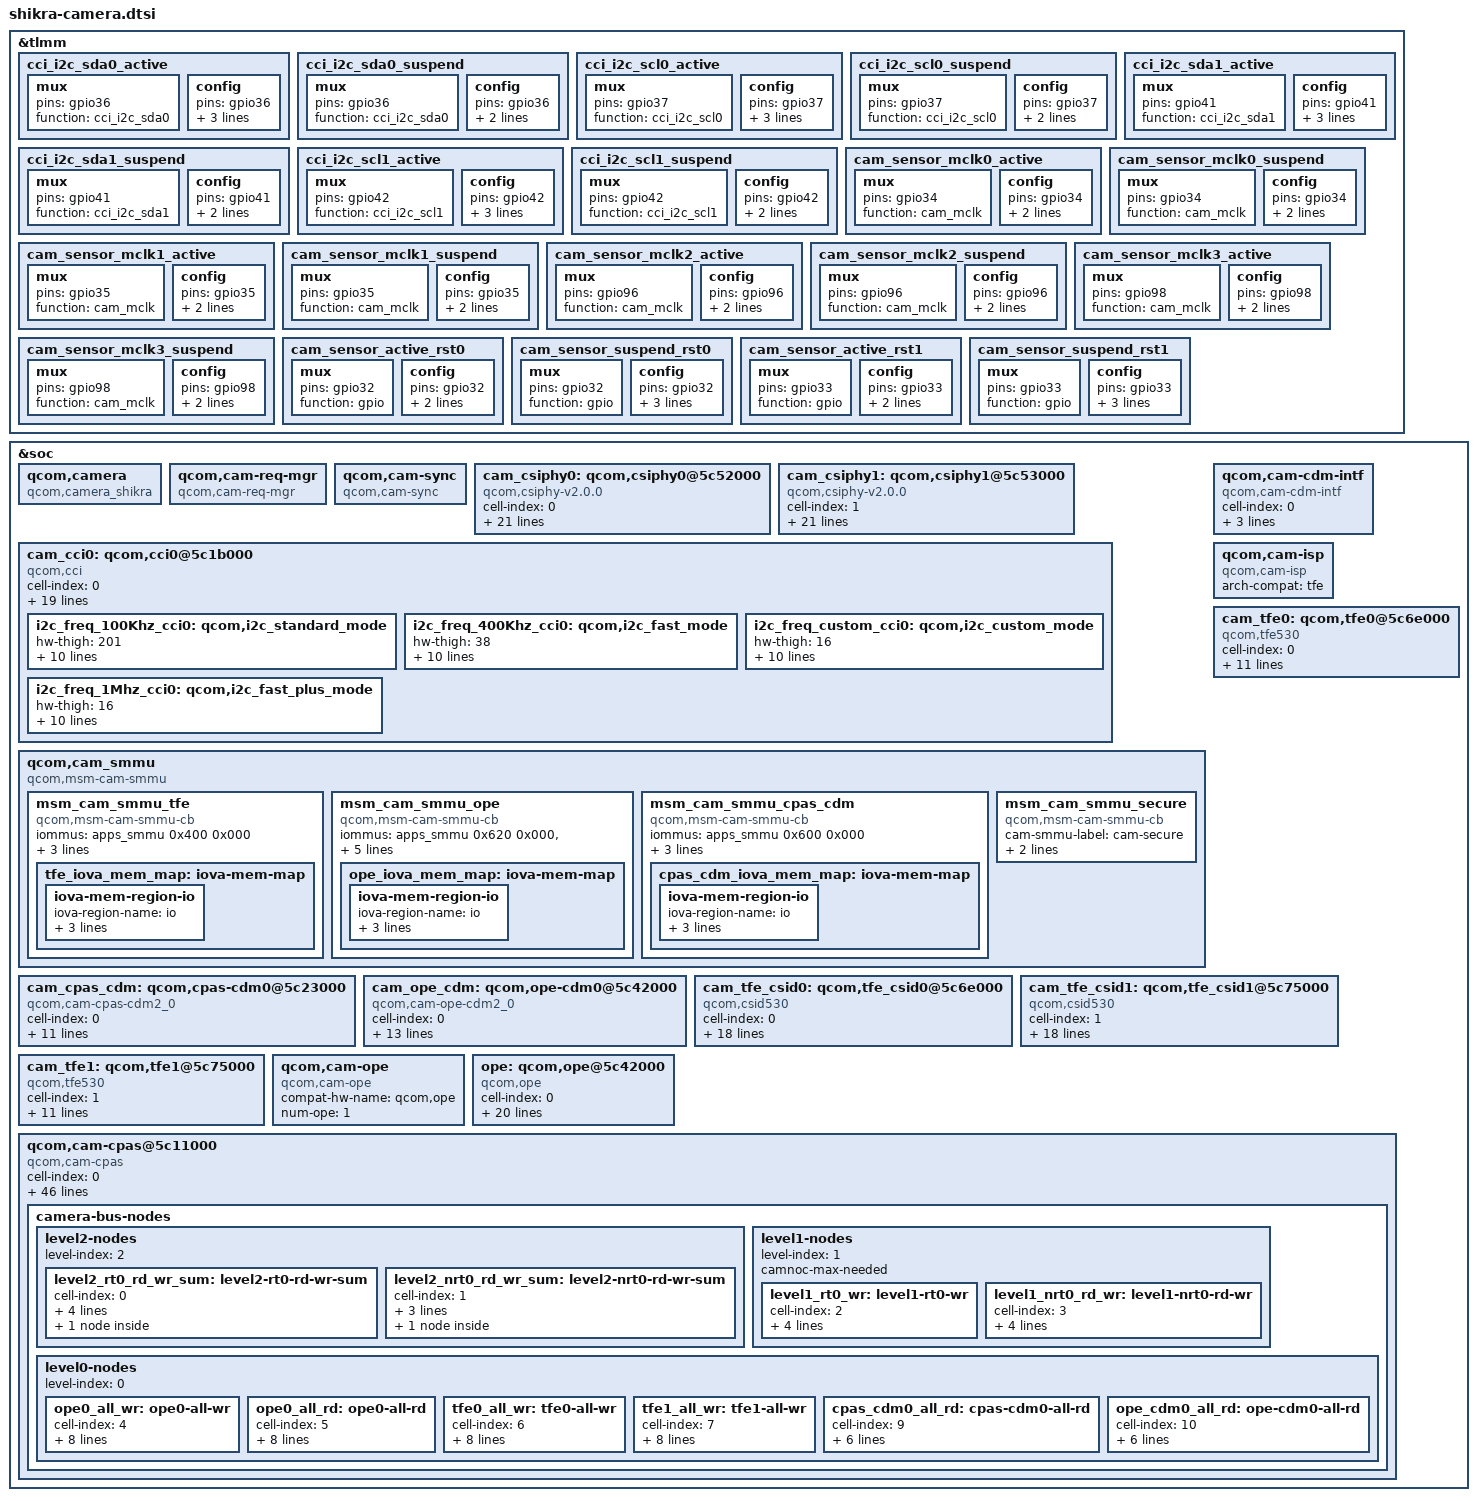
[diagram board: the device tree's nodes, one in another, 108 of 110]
// SPDX-License-Identifier: BSD-3-Clause
/*
 * Copyright (c) Qualcomm Technologies, Inc. and/or its subsidiaries.
 */

#include <dt-bindings/msm-camera.h>
#include <dt-bindings/interrupt-controller/arm-gic.h>
#include <dt-bindings/regulator/qcom,rpmh-regulator-levels.h>
#include <dt-bindings/clock/qcom,shikra-gcc.h>
#include <dt-bindings/interconnect/qcom,shikra.h>
#include <dt-bindings/arm/msm/qti-smmu-proxy-dt-ids.h>

&tlmm {
	cci_i2c_sda0_active: cci_i2c_sda0_active {
		mux {
			pins = "gpio36";
			function = "cci_i2c_sda0";
		};

		config {
			pins = "gpio36";
			bias-pull-up;
			drive-strength = <2>;
			qcom,i2c_pull;
		};
	};

	cci_i2c_sda0_suspend: cci_i2c_sda0_suspend {
		mux {
			pins = "gpio36";
			function = "cci_i2c_sda0";
		};

		config {
			pins = "gpio36";
			bias-pull-down;
			drive-strength = <2>;
		};
	};

	cci_i2c_scl0_active: cci_i2c_scl0_active {
		mux {
			pins = "gpio37";
			function = "cci_i2c_scl0";
		};

		config {
			pins = "gpio37";
			bias-pull-up;
			drive-strength = <2>;
			qcom,i2c_pull;
		};
	};

	cci_i2c_scl0_suspend: cci_i2c_scl0_suspend {
		mux {
			pins = "gpio37";
			function = "cci_i2c_scl0";
		};

		config {
			pins = "gpio37";
			bias-pull-down;
			drive-strength = <2>;
		};
	};

	cci_i2c_sda1_active: cci_i2c_sda1_active {
		mux {
			pins = "gpio41";
			function = "cci_i2c_sda1";
		};

		config {
			pins = "gpio41";
			bias-pull-up;
			drive-strength = <2>;
			qcom,i2c_pull;
		};
	};

	cci_i2c_sda1_suspend: cci_i2c_sda1_suspend {
		mux {
			pins = "gpio41";
			function = "cci_i2c_sda1";
		};

		config {
			pins = "gpio41";
			bias-pull-down;
			drive-strength = <2>;
		};
	};

	cci_i2c_scl1_active: cci_i2c_scl1_active {
		mux {
			pins = "gpio42";
			function = "cci_i2c_scl1";
		};

		config {
			pins = "gpio42";
			bias-pull-up;
			drive-strength = <2>;
			qcom,i2c_pull;
		};
	};

	cci_i2c_scl1_suspend: cci_i2c_scl1_suspend {
		mux {
			pins = "gpio42";
			function = "cci_i2c_scl1";
		};

		config {
			pins = "gpio42";
			bias-pull-down;
			drive-strength = <2>;
		};
	};

	cam_sensor_mclk0_active: cam_sensor_mclk0_active {
		mux {
			pins = "gpio34";
			function = "cam_mclk";
		};

		config {
			pins = "gpio34";
			bias-disable;
			drive-strength = <2>;
		};
	};

	cam_sensor_mclk0_suspend: cam_sensor_mclk0_suspend {
		mux {
			pins = "gpio34";
			function = "cam_mclk";
		};

		config {
			pins = "gpio34";
			bias-pull-down;
			drive-strength = <2>;
		};
	};

	cam_sensor_mclk1_active: cam_sensor_mclk1_active {
		mux {
			pins = "gpio35";
			function = "cam_mclk";
		};

		config {
			pins = "gpio35";
			bias-disable;
			drive-strength = <2>;
		};
	};

	cam_sensor_mclk1_suspend: cam_sensor_mclk1_suspend {
		mux {
			pins = "gpio35";
			function = "cam_mclk";
		};

		config {
			pins = "gpio35";
			bias-pull-down;
			drive-strength = <2>;
		};
	};

	cam_sensor_mclk2_active: cam_sensor_mclk2_active {
                mux {
                        pins = "gpio96";
                        function = "cam_mclk";
                };

                config {
                        pins = "gpio96";
                        bias-disable;
                        drive-strength = <2>;
                };
        };

        cam_sensor_mclk2_suspend: cam_sensor_mclk2_suspend {
                mux {
                        pins = "gpio96";
                        function = "cam_mclk";
                };

                config {
                        pins = "gpio96";
                        bias-pull-down;
                        drive-strength = <2>;
                };
        };

	cam_sensor_mclk3_active: cam_sensor_mclk3_active {
                mux {
                        pins = "gpio98";
                        function = "cam_mclk";
                };

                config {
                        pins = "gpio98";
                        bias-disable;
                        drive-strength = <2>;
                };
        };

        cam_sensor_mclk3_suspend: cam_sensor_mclk3_suspend {
                mux {
                        pins = "gpio98";
                        function = "cam_mclk";
                };

                config {
                        pins = "gpio98";
                        bias-pull-down;
                        drive-strength = <2>;
                };
        };

        cam_sensor_active_rst0: cam_sensor_active_rst0 {
                mux {
                        pins = "gpio32";
                        function = "gpio";
                };

                config {
                        pins = "gpio32";
                        bias-disable; /* No PULL */
                        drive-strength = <2>; /* 2 MA */
                };
        };

        cam_sensor_suspend_rst0: cam_sensor_suspend_rst0 {
                mux {
                        pins = "gpio32";
                        function = "gpio";
                };

                config {
                        pins = "gpio32";
                        bias-pull-down; /* PULL DOWN */
                        drive-strength = <2>; /* 2 MA */
                        output-low;
                };
        };

        cam_sensor_active_rst1: cam_sensor_active_rst1 {
                mux {
                        pins = "gpio33";
                        function = "gpio";
                };

                config {
                        pins = "gpio33";
                        bias-disable; /* No PULL */
                        drive-strength = <2>; /* 2 MA */
                };
        };

        cam_sensor_suspend_rst1: cam_sensor_suspend_rst1 {
                mux {
                        pins = "gpio33";
                        function = "gpio";
                };

                config {
                        pins = "gpio33";
                        bias-pull-down; /* PULL DOWN */
                        drive-strength = <2>; /* 2 MA */
                        output-low;
                };
        };
};

&soc {
	qcom,camera {
		compatible = "qcom,camera_shikra";
                status = "ok";
        };
	qcom,cam-req-mgr {
		compatible = "qcom,cam-req-mgr";
		status = "ok";
	};

	qcom,cam-sync {
		compatible = "qcom,cam-sync";
		status = "ok";
	};

	cam_csiphy0: qcom,csiphy0@5c52000 {
		cell-index = <0>;
		compatible = "qcom,csiphy-v2.0.0", "qcom,csiphy";
		reg = <0x5c52000 0x1000>;
		reg-names = "csiphy";
		reg-cam-base = <0x52000>;
		interrupt-names = "csiphy0";
		interrupts = <GIC_SPI 72 IRQ_TYPE_EDGE_RISING>;
		power-domains = <&gcc GCC_CAMSS_TOP_GDSC>;
		csi-vdd-1p2-supply = <&L5A>;
		regulator-names = "csi-vdd-1p2";
		rgltr-cntrl-support;
		rgltr-min-voltage = <1200000>;
		rgltr-max-voltage = <1200000>;
		rgltr-load-current = <26720>;
		shared-clks = <1 0 0 0>;
		clock-names = "cphy_rx_clk_src",
			"csiphy0_clk",
			"csi0phytimer_clk_src",
			"csi0phytimer_clk";
		clocks = <&gcc GCC_CAMSS_TFE_CPHY_RX_CLK_SRC>,
			<&gcc GCC_CAMSS_CPHY_0_CLK>,
			<&gcc GCC_CAMSS_CSI0PHYTIMER_CLK_SRC>,
			<&gcc GCC_CAMSS_CSI0PHYTIMER_CLK>;
		src-clock-name = "csi0phytimer_clk_src";
		clock-cntl-level = "lowsvs", "svs", "nominal", "turbo";
		clock-rates =
			<19200000 0 19200000 0>,
			<240000000 0 200000000 0>,
			<341330000 0 268800000 0>,
			<384000000 0 268800000 0>;
		status = "ok";
	};
	cam_csiphy1: qcom,csiphy1@5c53000 {
		cell-index = <1>;
		compatible = "qcom,csiphy-v2.0.0", "qcom,csiphy";
		reg = <0x5c53000 0x1000>;
		reg-names = "csiphy";
		reg-cam-base = <0x53000>;
		interrupt-names = "csiphy1";
		interrupts = <GIC_SPI 73 IRQ_TYPE_EDGE_RISING>;
		power-domains = <&gcc GCC_CAMSS_TOP_GDSC>;
		csi-vdd-1p2-supply = <&L5A>;
		regulator-names = "csi-vdd-1p2";
		rgltr-cntrl-support;
		rgltr-min-voltage = <1200000>;
		rgltr-max-voltage = <1200000>;
		rgltr-load-current = <26720>;
		shared-clks = <1 0 0 0>;
		clock-names = "cphy_rx_clk_src",
			"csiphy1_clk",
			"csi1phytimer_clk_src",
			"csi1phytimer_clk";
		clocks = <&gcc GCC_CAMSS_TFE_CPHY_RX_CLK_SRC>,
			<&gcc GCC_CAMSS_CPHY_1_CLK>,
			<&gcc GCC_CAMSS_CSI1PHYTIMER_CLK_SRC>,
			<&gcc GCC_CAMSS_CSI1PHYTIMER_CLK>;
		src-clock-name = "csi1phytimer_clk_src";
		clock-cntl-level = "lowsvs", "svs", "nominal", "turbo";
		clock-rates =
			<19200000 0 19200000 0>,
                        <240000000 0 200000000 0>,
                        <341330000 0 268800000 0>,
                        <384000000 0 268800000 0>;
		status = "ok";
	};

	cam_cci0: qcom,cci0@5c1b000 {
		cell-index = <0>;
		compatible = "qcom,cci", "simple-bus";
		#address-cells = <1>;
		#size-cells = <0>;
		reg = <0x5c1b000 0x1000>;
		reg-names = "cci";
		reg-cam-base = <0x1b000>;
		interrupt-names = "cci0";
		interrupts = <GIC_SPI 206 IRQ_TYPE_EDGE_RISING>;
		status = "ok";
		power-domains = <&gcc GCC_CAMSS_TOP_GDSC>;
		clock-names = "cci_0_clk_src",
			"cci_0_clk";
		clocks = <&gcc GCC_CAMSS_CCI_CLK_SRC>,
			<&gcc GCC_CAMSS_CCI_0_CLK>;
		clock-rates =
				<19200000 0>,
				<37500000 0>;
		clock-cntl-level = "lowsvs", "svs";
		src-clock-name = "cci_0_clk_src";
		pctrl-idx-mapping = <CCI_MASTER_0 CCI_MASTER_1>;
		pctrl-map-names = "m0", "m1";
		pinctrl-names = "m0_active", "m0_suspend",
			"m1_active", "m1_suspend";
		pinctrl-0 = <&cci_i2c_scl0_active &cci_i2c_sda0_active>;
		pinctrl-1 = <&cci_i2c_scl0_suspend &cci_i2c_sda0_suspend>;
		pinctrl-2 = <&cci_i2c_scl1_active &cci_i2c_sda1_active>;
		pinctrl-3 = <&cci_i2c_scl1_suspend &cci_i2c_sda1_suspend>;

		i2c_freq_100Khz_cci0: qcom,i2c_standard_mode {
			hw-thigh = <201>;
			hw-tlow = <174>;
			hw-tsu-sto = <204>;
			hw-tsu-sta = <231>;
			hw-thd-dat = <22>;
			hw-thd-sta = <162>;
			hw-tbuf = <227>;
			hw-scl-stretch-en = <0>;
			hw-trdhld = <6>;
			hw-tsp = <3>;
			cci-clk-src = <37500000>;
			status = "ok";
		};

		i2c_freq_400Khz_cci0: qcom,i2c_fast_mode {
			hw-thigh = <38>;
			hw-tlow = <56>;
			hw-tsu-sto = <40>;
			hw-tsu-sta = <40>;
			hw-thd-dat = <22>;
			hw-thd-sta = <35>;
			hw-tbuf = <62>;
			hw-scl-stretch-en = <1>;
			hw-trdhld = <6>;
			hw-tsp = <3>;
			cci-clk-src = <37500000>;
			status = "ok";
		};

		i2c_freq_custom_cci0: qcom,i2c_custom_mode {
			hw-thigh = <16>;
			hw-tlow = <22>;
			hw-tsu-sto = <17>;
			hw-tsu-sta = <18>;
			hw-thd-dat = <16>;
			hw-thd-sta = <15>;
			hw-tbuf = <24>;
			hw-scl-stretch-en = <1>;
			hw-trdhld = <3>;
			hw-tsp = <3>;
			cci-clk-src = <37500000>;
			status = "ok";
		};

		i2c_freq_1Mhz_cci0: qcom,i2c_fast_plus_mode {
			hw-thigh = <16>;
			hw-tlow = <22>;
			hw-tsu-sto = <17>;
			hw-tsu-sta = <18>;
			hw-thd-dat = <16>;
			hw-thd-sta = <15>;
			hw-tbuf = <24>;
			hw-scl-stretch-en = <1>;
			hw-trdhld = <3>;
			hw-tsp = <3>;
			cci-clk-src = <37500000>;
			status = "ok";
		};
	};

	qcom,cam_smmu {
		compatible = "qcom,msm-cam-smmu", "simple-bus";
		status = "ok";

		msm_cam_smmu_tfe {
			compatible = "qcom,msm-cam-smmu-cb";
			iommus = <&apps_smmu 0x400 0x000>;
			qcom,iommu-faults = "non-fatal";
			qcom,iommu-dma-addr-pool = <0x7400000 0xd8c00000>;
			cam-smmu-label = "tfe";
			tfe_iova_mem_map: iova-mem-map {
				iova-mem-region-io {
					iova-region-name = "io";
					iova-region-start = <0x7400000>;
					iova-region-len = <0xd8c00000>;
					iova-region-id = <0x3>;
					status = "ok";
				};
			};
		};

		msm_cam_smmu_ope {
			compatible = "qcom,msm-cam-smmu-cb";
			iommus = <&apps_smmu 0x620 0x000>,
				<&apps_smmu 0x640 0x000>;
			qcom,iommu-faults = "non-fatal";
			multiple-client-devices;
			qcom,iommu-dma-addr-pool = <0x7400000 0xd8c00000>;
			cam-smmu-label = "ope", "ope-cdm";
			ope_iova_mem_map: iova-mem-map {
				iova-mem-region-io {
					iova-region-name = "io";
					iova-region-start = <0x7400000>;
					iova-region-len = <0xd8c00000>;
					iova-region-id = <0x3>;
					status = "ok";
				};
			};
		};

		msm_cam_smmu_cpas_cdm {
			compatible = "qcom,msm-cam-smmu-cb";
			iommus = <&apps_smmu 0x600 0x000>;
			cam-smmu-label = "cpas-cdm";
			qcom,iommu-faults = "non-fatal";
			qcom,iommu-dma-addr-pool = <0x7400000 0xd8c00000>;
			cpas_cdm_iova_mem_map: iova-mem-map {
				iova-mem-region-io {
					iova-region-name = "io";
					iova-region-start = <0x7400000>;
					iova-region-len = <0xd8c00000>;
					iova-region-id = <0x3>;
					status = "ok";
				};
			};
		};

		msm_cam_smmu_secure {
			compatible = "qcom,msm-cam-smmu-cb";
			cam-smmu-label = "cam-secure";
			qcom,secure-cb;
			qti,smmu-proxy-cb-id = <QTI_SMMU_PROXY_CAMERA_CB>;
		};
	};

	qcom,cam-cdm-intf {
		compatible = "qcom,cam-cdm-intf";
		cell-index = <0>;
		label = "cam-cdm-intf";
		num-hw-cdm = <2>;
		cdm-client-names = "vfe";
		status = "ok";
	};

	cam_cpas_cdm: qcom,cpas-cdm0@5c23000 {
		cell-index = <0>;
		compatible = "qcom,cam-cpas-cdm2_0";
		label = "cpas-cdm";
		reg = <0x5c23000 0x400>;
		reg-names = "cpas-cdm0";
		reg-cam-base = <0x23000>;
		interrupts = <GIC_SPI 207 IRQ_TYPE_EDGE_RISING>;
		interrupt-names = "cpas-cdm0";
		power-domains = <&gcc GCC_CAMSS_TOP_GDSC>;
		clock-names = "cam_cc_cpas_top_ahb_clk";
		clocks = <&gcc GCC_CAMSS_TOP_AHB_CLK>;
		clock-rates = <0>;
		clock-cntl-level = "svs";
		cdm-client-names = "tfe0", "tfe1";
		config-fifo;
		fifo-depths = <64 64 64 64>;
		status = "ok";
	};

	cam_ope_cdm: qcom,ope-cdm0@5c42000 {
		cell-index = <0>;
		compatible = "qcom,cam-ope-cdm2_0";
		label = "ope-cdm";
		reg = <0x5c42000 0x400>;
		reg-names = "ope-cdm0";
		reg-cam-base = <0x42000>;
		interrupts = <GIC_SPI 208 IRQ_TYPE_EDGE_RISING>;
		interrupt-names = "ope-cdm0";
		power-domains = <&gcc GCC_CAMSS_TOP_GDSC>;
		clock-names =
			"ope_ahb_clk",
			"ope_clk_src",
			"ope_clk";
		clocks =
			<&gcc GCC_CAMSS_OPE_AHB_CLK>,
			<&gcc GCC_CAMSS_OPE_CLK_SRC>,
			<&gcc GCC_CAMSS_OPE_CLK>;
		clock-rates = <0 0 0>,
			<0 0 0>,
			<0 0 0>,
			<0 0 0>;
		clock-cntl-level = "lowsvs", "svs", "svs_l1", "turbo";
		cdm-client-names = "ope";
		config-fifo;
		fifo-depths = <64 64 64 64>;
		status = "ok";
	};

	qcom,cam-isp {
		compatible = "qcom,cam-isp";
		arch-compat = "tfe";
		status = "ok";
	};

	cam_tfe_csid0: qcom,tfe_csid0@5c6e000 {
		cell-index = <0>;
		compatible = "qcom,csid530";
		reg-names = "csid", "top", "camnoc";
		reg = <0x5c6e000 0x1000>,
			<0x5c11000 0x1000>,
			<0x5c13000 0x4000>;
		reg-cam-base = <0x6e000 0x11000 0x13000>;
		interrupt-names = "csid0";
		interrupts = <GIC_SPI 210 IRQ_TYPE_EDGE_RISING>;
		power-domains = <&gcc GCC_CAMSS_TOP_GDSC>;
		clock-names =
			"tfe_csid_clk_src",
			"tfe_csid_clk",
			"cphy_rx_clk_src",
			"tfe_cphy_rx_clk",
			"tfe_clk_src",
			"tfe_clk";
		clocks =
			<&gcc GCC_CAMSS_TFE_0_CSID_CLK_SRC>,
			<&gcc GCC_CAMSS_TFE_0_CSID_CLK>,
			<&gcc GCC_CAMSS_TFE_CPHY_RX_CLK_SRC>,
			<&gcc GCC_CAMSS_TFE_0_CPHY_RX_CLK>,
			<&gcc GCC_CAMSS_TFE_0_CLK_SRC>,
			<&gcc GCC_CAMSS_TFE_0_CLK>;
		clock-rates =
			<19200000 0 19200000 0 19200000 0>,
			<240000000 0 240000000 0 256000000 0>,
			<384000000 0 341333333 0 460800000 0>,
			<426400000 0 384000000 0 576000000 0>;
		clock-cntl-level = "lowsvs", "svs", "svs_l1", "turbo";
		src-clock-name = "tfe_csid_clk_src";
		clock-control-debugfs = "true";
		status = "ok";
	};

	cam_tfe0: qcom,tfe0@5c6e000 {
		cell-index = <0>;
		compatible = "qcom,tfe530";
		reg-names = "tfe0";
		reg = <0x5c6e000 0x5000>;
		reg-cam-base = <0x6e000>;
		interrupt-names = "tfe0";
		interrupts = <GIC_SPI 211 IRQ_TYPE_EDGE_RISING>;
		power-domains = <&gcc GCC_CAMSS_TOP_GDSC>;
		clock-names =
			"tfe_clk_src",
			"tfe_clk";
		clocks =
			<&gcc GCC_CAMSS_TFE_0_CLK_SRC>,
			<&gcc GCC_CAMSS_TFE_0_CLK>;
		clock-rates =
			<19200000 0>,
			<256000000 0>,
			<460800000 0>,
			<576000000 0>;
		clock-cntl-level = "lowsvs", "svs", "svs_l1", "turbo";
		src-clock-name = "tfe_clk_src";
		clock-control-debugfs = "true";
		status = "ok";
	};

	cam_tfe_csid1: qcom,tfe_csid1@5c75000 {
		cell-index = <1>;
		compatible = "qcom,csid530";
		reg-names = "csid", "top", "camnoc";
		reg = <0x5c75000 0x1000>,
			<0x5c11000 0x1000>,
			<0x5c13000 0x4000>;
		reg-cam-base = <0x75000 0x11000 0x13000>;
		interrupt-names = "csid1";
		interrupts = <GIC_SPI 212 IRQ_TYPE_EDGE_RISING>;
		power-domains = <&gcc GCC_CAMSS_TOP_GDSC>;
		clock-names =
			"tfe_csid_clk_src",
			"tfe_csid_clk",
			"cphy_rx_clk_src",
			"tfe_cphy_rx_clk",
			"tfe_clk_src",
			"tfe_clk";
		clocks =
			<&gcc GCC_CAMSS_TFE_1_CSID_CLK_SRC>,
			<&gcc GCC_CAMSS_TFE_1_CSID_CLK>,
			<&gcc GCC_CAMSS_TFE_CPHY_RX_CLK_SRC>,
			<&gcc GCC_CAMSS_TFE_1_CPHY_RX_CLK>,
			<&gcc GCC_CAMSS_TFE_1_CLK_SRC>,
			<&gcc GCC_CAMSS_TFE_1_CLK>;
		clock-rates =
			<19200000 0 19200000 0 19200000 0>,
			<240000000 0 240000000 0 256000000 0>,
			<384000000 0 341333333 0 460800000 0>,
			<426400000 0 384000000 0 576000000 0>;
		clock-cntl-level = "lowsvs", "svs", "svs_l1", "turbo";
		src-clock-name = "tfe_csid_clk_src";
		clock-control-debugfs = "true";
		status = "ok";
	};

	cam_tfe1: qcom,tfe1@5c75000 {
		cell-index = <1>;
		compatible = "qcom,tfe530";
		reg-names = "tfe1";
		reg = <0x5c75000 0x5000>;
		reg-cam-base = <0x75000>;
		interrupt-names = "tfe1";
		interrupts = <GIC_SPI 213 IRQ_TYPE_EDGE_RISING>;
		power-domains = <&gcc GCC_CAMSS_TOP_GDSC>;
		clock-names =
			"tfe_clk_src",
			"tfe_clk";
		clocks =
			<&gcc GCC_CAMSS_TFE_1_CLK_SRC>,
			<&gcc GCC_CAMSS_TFE_1_CLK>;
		clock-rates =
			<19200000 0>,
			<256000000 0>,
			<460800000 0>,
			<576000000 0>;
		clock-cntl-level = "lowsvs", "svs", "svs_l1", "turbo";
		src-clock-name = "tfe_clk_src";
		clock-control-debugfs = "true";
		status = "ok";
	};

	qcom,cam-ope {
		compatible = "qcom,cam-ope";
		compat-hw-name = "qcom,ope";
		num-ope = <1>;
		status = "ok";
	};

	ope: qcom,ope@5c42000 {
		cell-index = <0>;
		compatible = "qcom,ope";
		reg =
			<0x5c42000 0x400>,
			<0x5c42400 0x200>,
			<0x5c42600 0x200>,
			<0x5c42800 0x4400>,
			<0x5c46c00 0x190>,
			<0x5c46d90 0xA00>;
		reg-names =
			"ope_cdm",
			"ope_top",
			"ope_qos",
			"ope_pp",
			"ope_bus_rd",
			"ope_bus_wr";
		reg-cam-base = <0x42000 0x42400 0x42600 0x42800 0x46c00 0x46d90>;
		interrupts = <GIC_SPI 209 IRQ_TYPE_EDGE_RISING>;
		interrupt-names = "ope";
		power-domains = <&gcc GCC_CAMSS_TOP_GDSC>;
		clock-names =
			"ope_ahb_clk_src",
			"ope_ahb_clk",
			"ope_clk_src",
			"ope_clk";
		clocks =
			<&gcc GCC_CAMSS_OPE_AHB_CLK_SRC>,
			<&gcc GCC_CAMSS_OPE_AHB_CLK>,
			<&gcc GCC_CAMSS_OPE_CLK_SRC>,
			<&gcc GCC_CAMSS_OPE_CLK>;
		clock-rates =
			<19200000 0 19200000 0>,
			<171428571 0 200000000 0>,
			<171428571 0 266600000 0>,
			<240000000 0 465000000 0>,
			<240000000 0 580000000 0>;
		clock-cntl-level = "lowsvs", "svs", "svs_l1", "nominal", "turbo";
		src-clock-name = "ope_clk_src";
		clock-control-debugfs = "true";
		status = "ok";
	};

	qcom,cam-cpas@5c11000 {
		cell-index = <0>;
		compatible = "qcom,cam-cpas";
		label = "cpas";
		arch-compat = "cpas_top";
		status = "ok";
		reg-names = "cam_cpas_top", "cam_camnoc";
		reg = <0x5c11000 0x1000>,
			<0x5c13000 0x4000>;
		reg-cam-base = <0x11000 0x13000>;
		interrupt-names = "cpas_camnoc";
		interrupts = <GIC_SPI 159 IRQ_TYPE_EDGE_RISING>;
		camnoc-axi-min-ib-bw = <3000000000>;
		power-domains = <&gcc GCC_CAMSS_TOP_GDSC>;
		clock-names =
			"gcc_camss_top_ahb_clk",
			"gcc_camss_top_ahb_clk_src",
			"gcc_camss_axi_clk",
			"gcc_camss_axi_clk_src",
			"gcc_camss_nrt_axi_clk",
			"gcc_camss_rt_axi_clk";
		clocks =
			<&gcc GCC_CAMSS_TOP_AHB_CLK>,
			<&gcc GCC_CAMSS_TOP_AHB_CLK_SRC>,
			<&gcc GCC_CAMSS_AXI_CLK>,
			<&gcc GCC_CAMSS_AXI_CLK_SRC>,
			<&gcc GCC_CAMSS_NRT_AXI_CLK>,
			<&gcc GCC_CAMSS_RT_AXI_CLK>;
		src-clock-name = "gcc_camss_axi_clk_src";
		clock-rates =
                        <0        0 0         0 0 0>,
                        <0 19000000 0  19200000 0 0>,
                        <0 80000000 0 150000000 0 0>,
                        <0 80000000 0 200000000 0 0>,
                        <0 80000000 0 300000000 0 0>,
                        <0 80000000 0 300000000 0 0>,
                        <0 80000000 0 300000000 0 0>;
                clock-cntl-level = "suspend", "lowsvs", "svs",
			"svs_l1", "nominal","nominal_l1", "turbo";
		control-camnoc-axi-clk;
		camnoc-bus-width = <32>;
		camnoc-axi-clk-bw-margin-perc = <20>;
		cam-icc-path-names = "cam_ahb";
		interconnect-names = "cam_ahb", "cam_hf_0", "cam_sf_0";
                interconnects =
				    <&mem_noc MASTER_AMPSS_M0 &config_noc SLAVE_CAMERA_CFG>,
                    <&mmrt_virt MASTER_CAMNOC_HF &mc_virt SLAVE_EBI_CH0>,
                    <&mmnrt_virt MASTER_CAMNOC_SF &mc_virt SLAVE_EBI_CH0>;
                cam-ahb-num-cases = <7>;
                cam-ahb-bw-KBps =
                        <0 0>, <0 133333>, <0 150000>, <0 150000>,
                        <0 300000>, <0 300000>, <0 300000>;
                vdd-corners = <RPMH_REGULATOR_LEVEL_RETENTION
			RPMH_REGULATOR_LEVEL_MIN_SVS
			RPMH_REGULATOR_LEVEL_LOW_SVS
			RPMH_REGULATOR_LEVEL_LOW_SVS_L1
			RPMH_REGULATOR_LEVEL_LOW_SVS_L2
			RPMH_REGULATOR_LEVEL_SVS
			RPMH_REGULATOR_LEVEL_SVS_L0
			RPMH_REGULATOR_LEVEL_SVS_L1
			RPMH_REGULATOR_LEVEL_SVS_L2
			RPMH_REGULATOR_LEVEL_NOM
			RPMH_REGULATOR_LEVEL_NOM_L1
			RPMH_REGULATOR_LEVEL_NOM_L2
			RPMH_REGULATOR_LEVEL_TURBO
			RPMH_REGULATOR_LEVEL_TURBO_L1>;
		vdd-corner-ahb-mapping = "suspend", "lowsvs", "lowsvs",
			"lowsvs", "lowsvs", "svs", "svs_l1", "svs_l1",
			"svs_l1", "nominal", "nominal", "nominal",
			"turbo", "turbo";
		client-id-based;
		client-names =
			"csiphy0", "csiphy1", "cci0",
			"csid0", "csid1", "tfe0",
			"tfe1", "ope0", "cam-cdm-intf0",
			"cpas-cdm0", "ope-cdm0";

		camera-bus-nodes {
			level2-nodes {
				level-index = <2>;
				level2_rt0_rd_wr_sum: level2-rt0-rd-wr-sum {
					cell-index = <0>;
					node-name = "level2-rt0-rd-wr-sum";
					traffic-merge-type =
					<CAM_CPAS_TRAFFIC_MERGE_SUM>;
					qcom,axi-port-name = "cam_hf_0";
					ib-bw-voting-needed;
					qcom,axi-port-mnoc {
                                                cam-icc-path-names = "cam_hf_0";
					};
				};

				level2_nrt0_rd_wr_sum: level2-nrt0-rd-wr-sum {
					cell-index = <1>;
					node-name = "level2-nrt0-rd-wr-sum";
					traffic-merge-type =
					<CAM_CPAS_TRAFFIC_MERGE_SUM>;
					qcom,axi-port-name = "cam_sf_0";
					qcom,axi-port-mnoc {
                                                cam-icc-path-names = "cam_sf_0";
					};
				};
			};

			level1-nodes {
				level-index = <1>;
				camnoc-max-needed;
				level1_rt0_wr: level1-rt0-wr {
					cell-index = <2>;
					node-name = "level1-rt0-wr";
					parent-node = <&level2_rt0_rd_wr_sum>;
					traffic-merge-type =
					<CAM_CPAS_TRAFFIC_MERGE_SUM_INTERLEAVE>;
				};

				level1_nrt0_rd_wr: level1-nrt0-rd-wr {
					cell-index = <3>;
					node-name = "level1-nrt0-rd-wr";
					parent-node = <&level2_nrt0_rd_wr_sum>;
					traffic-merge-type =
					<CAM_CPAS_TRAFFIC_MERGE_SUM_INTERLEAVE>;
				};
			};

			level0-nodes {
				level-index = <0>;
				ope0_all_wr: ope0-all-wr {
					cell-index = <4>;
					node-name = "ope0-all-wr";
					client-name = "ope0";
					traffic-data = <CAM_CPAS_PATH_DATA_ALL>;
					traffic-transaction-type =
					<CAM_CPAS_TRANSACTION_WRITE>;
					constituent-paths =
						<CAM_CPAS_PATH_DATA_OPE_WR_VID
						CAM_CPAS_PATH_DATA_OPE_WR_DISP
						CAM_CPAS_PATH_DATA_OPE_WR_REF>;
					parent-node = <&level1_nrt0_rd_wr>;
				};

				ope0_all_rd: ope0-all-rd {
					cell-index = <5>;
					node-name = "ope0-all-rd";
					client-name = "ope0";
					traffic-data = <CAM_CPAS_PATH_DATA_ALL>;
					traffic-transaction-type =
					<CAM_CPAS_TRANSACTION_READ>;
					constituent-paths =
						<CAM_CPAS_PATH_DATA_OPE_RD_IN
						CAM_CPAS_PATH_DATA_OPE_RD_REF>;
					parent-node = <&level1_nrt0_rd_wr>;
				};

				tfe0_all_wr: tfe0-all-wr {
					cell-index = <6>;
					node-name = "tfe0-all-wr";
					client-name = "tfe0";
					traffic-data = <CAM_CPAS_PATH_DATA_ALL>;
					traffic-transaction-type =
					<CAM_CPAS_TRANSACTION_WRITE>;
					constituent-paths =
						<CAM_CPAS_PATH_DATA_IFE_RDI0
						CAM_CPAS_PATH_DATA_IFE_RDI1
						CAM_CPAS_PATH_DATA_IFE_RDI2
						CAM_CPAS_PATH_DATA_IFE_RDI3
						CAM_CPAS_PATH_DATA_IFE_VID
						CAM_CPAS_PATH_DATA_IFE_DISP
						CAM_CPAS_PATH_DATA_IFE_STATS>;
					parent-node = <&level1_rt0_wr>;
				};

				tfe1_all_wr: tfe1-all-wr {
					cell-index = <7>;
					node-name = "tfe1-all-wr";
					client-name = "tfe1";
					traffic-data = <CAM_CPAS_PATH_DATA_ALL>;
					traffic-transaction-type =
					<CAM_CPAS_TRANSACTION_WRITE>;
					constituent-paths =
						<CAM_CPAS_PATH_DATA_IFE_RDI0
						CAM_CPAS_PATH_DATA_IFE_RDI1
						CAM_CPAS_PATH_DATA_IFE_RDI2
						CAM_CPAS_PATH_DATA_IFE_RDI3
						CAM_CPAS_PATH_DATA_IFE_VID
						CAM_CPAS_PATH_DATA_IFE_DISP
						CAM_CPAS_PATH_DATA_IFE_STATS>;
					parent-node = <&level1_rt0_wr>;
				};

				cpas_cdm0_all_rd: cpas-cdm0-all-rd {
					cell-index = <9>;
					node-name = "cpas-cdm0-all-rd";
					client-name = "cpas-cdm0";
					traffic-data = <CAM_CPAS_PATH_DATA_ALL>;
					traffic-transaction-type =
					<CAM_CPAS_TRANSACTION_READ>;
					parent-node = <&level1_nrt0_rd_wr>;
				};

				ope_cdm0_all_rd: ope-cdm0-all-rd {
					cell-index = <10>;
					node-name = "ope-cdm0-all-rd";
					client-name = "ope-cdm0";
					traffic-data = <CAM_CPAS_PATH_DATA_ALL>;
					traffic-transaction-type =
					<CAM_CPAS_TRANSACTION_READ>;
					parent-node = <&level1_nrt0_rd_wr>;
				};
			};
		};
	};
};
